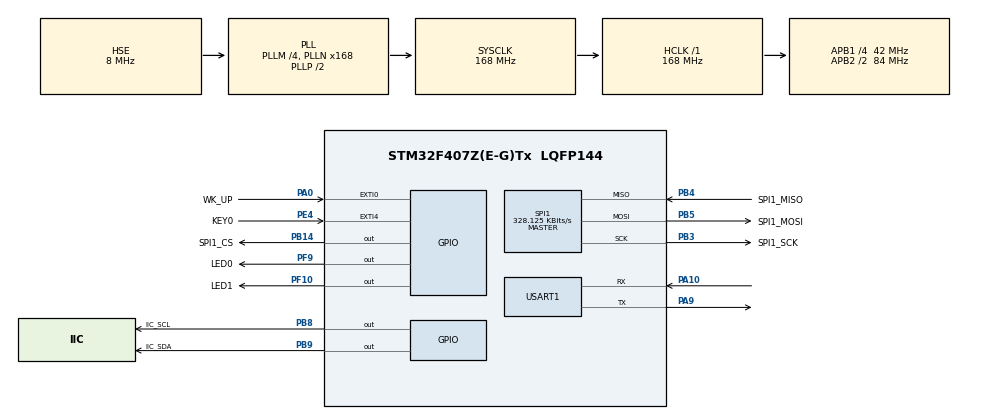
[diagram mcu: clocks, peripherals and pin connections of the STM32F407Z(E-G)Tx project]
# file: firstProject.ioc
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Dma.Request0=USART1_RX
Dma.USART1_RX.0.Direction=DMA_PERIPH_TO_MEMORY
Dma.USART1_RX.0.FIFOMode=DMA_FIFOMODE_DISABLE
Dma.USART1_RX.0.Instance=DMA2_Stream2
Dma.USART1_RX.0.MemDataAlignment=DMA_MDATAALIGN_BYTE
Dma.USART1_RX.0.MemInc=DMA_MINC_ENABLE
Dma.USART1_RX.0.Mode=DMA_NORMAL
Dma.USART1_RX.0.PeriphDataAlignment=DMA_PDATAALIGN_BYTE
Dma.USART1_RX.0.PeriphInc=DMA_PINC_DISABLE
Dma.USART1_RX.0.Priority=DMA_PRIORITY_LOW
IWDG.Prescaler=IWDG_PRESCALER_64
IWDG.Reload=2000
Mcu.Family=STM32F4
Mcu.Name=STM32F407Z(E-G)Tx
Mcu.Package=LQFP144
NVIC.DMA2_Stream2_IRQn=true\:1\:0\:true\:false\:true\:false\:true
NVIC.EXTI0_IRQn=true\:2\:0\:true\:false\:true\:true\:true
NVIC.EXTI4_IRQn=true\:2\:0\:true\:false\:true\:true\:true
NVIC.PriorityGroup=NVIC_PRIORITYGROUP_4
NVIC.TIM8_TRG_COM_TIM14_IRQn=true\:1\:0\:true\:false\:true\:true\:true
NVIC.USART1_IRQn=true\:3\:0\:true\:false\:true\:true\:true
PA0-WKUP.GPIO_Label=WK_UP
PA0-WKUP.GPIO_PuPd=GPIO_PULLDOWN
PA0-WKUP.Signal=GPXTI0
PA10.Mode=Asynchronous
PA10.Signal=USART1_RX
PA13.Mode=Serial_Wire
PA13.Signal=SYS_JTMS-SWDIO
PA14.Mode=Serial_Wire
PA14.Signal=SYS_JTCK-SWCLK
PA9.Mode=Asynchronous
PA9.Signal=USART1_TX
PB14.GPIO_Label=SPI1_CS
PB14.GPIO_ModeDefaultOutputPP=GPIO_MODE_OUTPUT_PP
PB14.GPIO_PuPd=GPIO_PULLUP
PB14.GPIO_Speed=GPIO_SPEED_FREQ_HIGH
PB14.PinState=GPIO_PIN_SET
PB14.Signal=GPIO_Output
PB3.GPIO_Label=SPI1_SCK
PB3.GPIO_PuPd=GPIO_PULLUP
PB3.GPIO_Speed=GPIO_SPEED_FREQ_VERY_HIGH
PB3.Mode=Full_Duplex_Master
PB3.Signal=SPI1_SCK
PB4.GPIO_Label=SPI1_MISO
PB4.GPIO_PuPd=GPIO_PULLUP
PB4.GPIO_Speed=GPIO_SPEED_FREQ_VERY_HIGH
PB4.Mode=Full_Duplex_Master
PB4.Signal=SPI1_MISO
PB5.GPIO_Label=SPI1_MOSI
PB5.GPIO_PuPd=GPIO_PULLUP
PB5.GPIO_Speed=GPIO_SPEED_FREQ_VERY_HIGH
PB5.Mode=Full_Duplex_Master
PB5.Signal=SPI1_MOSI
PB8.GPIO_Label=IIC_SCL
PB8.GPIO_PuPd=GPIO_PULLUP
PB8.GPIO_Speed=GPIO_SPEED_FREQ_HIGH
PB8.Signal=GPIO_Output
PB9.GPIO_Label=IIC_SDA
PB9.GPIO_PuPd=GPIO_PULLUP
PB9.GPIO_Speed=GPIO_SPEED_FREQ_HIGH
PB9.Signal=GPIO_Output
PC14-OSC32_IN.Mode=LSE-External-Oscillator
PC14-OSC32_IN.Signal=RCC_OSC32_IN
PC15-OSC32_OUT.Mode=LSE-External-Oscillator
PC15-OSC32_OUT.Signal=RCC_OSC32_OUT
PE4.GPIO_Label=KEY0
PE4.GPIO_ModeDefaultEXTI=GPIO_MODE_IT_RISING
PE4.GPIO_PuPd=GPIO_PULLDOWN
PE4.Signal=GPXTI4
PF10.GPIO_Label=LED1
PF10.GPIO_PuPd=GPIO_PULLUP
PF10.GPIO_Speed=GPIO_SPEED_FREQ_HIGH
PF10.PinState=GPIO_PIN_SET
PF10.Signal=GPIO_Output
PF9.GPIO_Label=LED0
PF9.GPIO_PuPd=GPIO_PULLUP
PF9.GPIO_Speed=GPIO_SPEED_FREQ_HIGH
PF9.PinState=GPIO_PIN_SET
PF9.Signal=GPIO_Output
PH0-OSC_IN.Mode=HSE-External-Oscillator
PH0-OSC_IN.Signal=RCC_OSC_IN
PH1-OSC_OUT.Mode=HSE-External-Oscillator
PH1-OSC_OUT.Signal=RCC_OSC_OUT
ProjectManager.HeapSize=0x200
ProjectManager.StackSize=0x400
ProjectManager.TargetToolchain=STM32CubeIDE
RCC.48MHZClocksFreq_Value=84000000
RCC.AHBFreq_Value=168000000
RCC.APB1CLKDivider=RCC_HCLK_DIV4
RCC.APB1Freq_Value=42000000
RCC.APB1TimFreq_Value=84000000
RCC.APB2CLKDivider=RCC_HCLK_DIV2
RCC.APB2Freq_Value=84000000
RCC.APB2TimFreq_Value=168000000
RCC.CortexFreq_Value=168000000
RCC.HCLKFreq_Value=168000000
RCC.HSE_VALUE=8000000
RCC.HSI_VALUE=16000000
RCC.PLLM=4
RCC.PLLN=168
RCC.PLLSourceVirtual=RCC_PLLSOURCE_HSE
RCC.SYSCLKFreq_VALUE=168000000
RCC.SYSCLKSource=RCC_SYSCLKSOURCE_PLLCLK
RCC.VCOOutputFreq_Value=336000000
SPI1.BaudRatePrescaler=SPI_BAUDRATEPRESCALER_256
SPI1.CLKPhase=SPI_PHASE_2EDGE
SPI1.CLKPolarity=SPI_POLARITY_HIGH
SPI1.CRCCalculation=SPI_CRCCALCULATION_DISABLE
SPI1.CalculateBaudRate=328.125 KBits/s
SPI1.Direction=SPI_DIRECTION_2LINES
SPI1.Mode=SPI_MODE_MASTER
SPI1.VirtualType=VM_MASTER
TIM14.AutoReloadPreload=TIM_AUTORELOAD_PRELOAD_ENABLE
TIM14.Period=4999
TIM14.Prescaler=8399
USART1.VirtualMode=VM_ASYNC
VP_IWDG_VS_IWDG.Mode=IWDG_Activate
VP_TIM14_VS_ClockSourceINT.Mode=Enable_Timer
board=custom

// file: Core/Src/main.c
/* USER CODE BEGIN Header */
/**
  ******************************************************************************
  * @file           : main.c
  * @brief          : Main program body
  ******************************************************************************
  * @attention
  *
  * <h2><center>&copy; Copyright (c) 2023 STMicroelectronics.
  * All rights reserved.</center></h2>
  *
  * This software component is licensed by ST under BSD 3-Clause license,
  * the "License"; You may not use this file except in compliance with the
  * License. You may obtain a copy of the License at:
  *                        opensource.org/licenses/BSD-3-Clause
  *
  ******************************************************************************
  */
/* USER CODE END Header */
#include "main.h"
#include "dma.h"
#include "iwdg.h"
#include "spi.h"
#include "tim.h"
#include "usart.h"
#include "gpio.h"

/* USER CODE BEGIN Includes */
#include "stdio.h"
#include "led.h"
#include "key.h"
#include "myiic.h"
#include "norflash.h"
#include "at24c02.h"
/* USER CODE END Includes */

void SystemClock_Config(void);

int main(void)
{

  /* MCU Configuration--------------------------------------------------------*/

  /* Reset of all peripherals, Initializes the Flash interface and the Systick. */
  HAL_Init();

  /* Configure the system clock */
  SystemClock_Config();

  /* USER CODE BEGIN SysInit */
  MX_DMA_Init();				//�?要在USART_Init之前先初始化DMA_Init，原因是USART中有关于DMA的配置，要进行DMA的配置，�?要先在DMA_Init中开启时�?
  /* USER CODE END SysInit */

  /* Initialize all configured peripherals */
  MX_GPIO_Init();
  MX_USART1_UART_Init();
  MX_TIM14_Init();
  MX_DMA_Init();
  MX_SPI1_Init();
  MX_IWDG_Init();
  /* USER CODE BEGIN 2 */
  IIC_Init();
  printf("reset\r\n");
  /* USER CODE END 2 */

  /* Infinite loop */
  /* USER CODE BEGIN WHILE */
  while (1)
  {
	  HAL_Delay(500);
	  HAL_IWDG_Refresh(&hiwdg);			//独立看门狗时间约为4.4s
    /* USER CODE END WHILE */

  }
}

void SystemClock_Config(void)
{
  RCC_OscInitTypeDef RCC_OscInitStruct = {0};
  RCC_ClkInitTypeDef RCC_ClkInitStruct = {0};

  /** Configure the main internal regulator output voltage
  */
  __HAL_RCC_PWR_CLK_ENABLE();
  __HAL_PWR_VOLTAGESCALING_CONFIG(PWR_REGULATOR_VOLTAGE_SCALE1);
  /** Initializes the RCC Oscillators according to the specified parameters
  * in the RCC_OscInitTypeDef structure.
  */
  RCC_OscInitStruct.OscillatorType = RCC_OSCILLATORTYPE_LSI|RCC_OSCILLATORTYPE_HSE;
  RCC_OscInitStruct.HSEState = RCC_HSE_ON;
  RCC_OscInitStruct.LSIState = RCC_LSI_ON;
  RCC_OscInitStruct.PLL.PLLState = RCC_PLL_ON;
  RCC_OscInitStruct.PLL.PLLSource = RCC_PLLSOURCE_HSE;
  RCC_OscInitStruct.PLL.PLLM = 4;
  RCC_OscInitStruct.PLL.PLLN = 168;
  RCC_OscInitStruct.PLL.PLLP = RCC_PLLP_DIV2;
  RCC_OscInitStruct.PLL.PLLQ = 4;
  if (HAL_RCC_OscConfig(&RCC_OscInitStruct) != HAL_OK)
  {
    Error_Handler();
  }
  /** Initializes the CPU, AHB and APB buses clocks
  */
  RCC_ClkInitStruct.ClockType = RCC_CLOCKTYPE_HCLK|RCC_CLOCKTYPE_SYSCLK
                              |RCC_CLOCKTYPE_PCLK1|RCC_CLOCKTYPE_PCLK2;
  RCC_ClkInitStruct.SYSCLKSource = RCC_SYSCLKSOURCE_PLLCLK;
  RCC_ClkInitStruct.AHBCLKDivider = RCC_SYSCLK_DIV1;
  RCC_ClkInitStruct.APB1CLKDivider = RCC_HCLK_DIV4;
  RCC_ClkInitStruct.APB2CLKDivider = RCC_HCLK_DIV2;

  if (HAL_RCC_ClockConfig(&RCC_ClkInitStruct, FLASH_LATENCY_5) != HAL_OK)
  {
    Error_Handler();
  }
}

void Error_Handler(void)
{
  __disable_irq();
  while (1)
  {
  }
}

/************************ (C) COPYRIGHT STMicroelectronics *****END OF FILE****/
